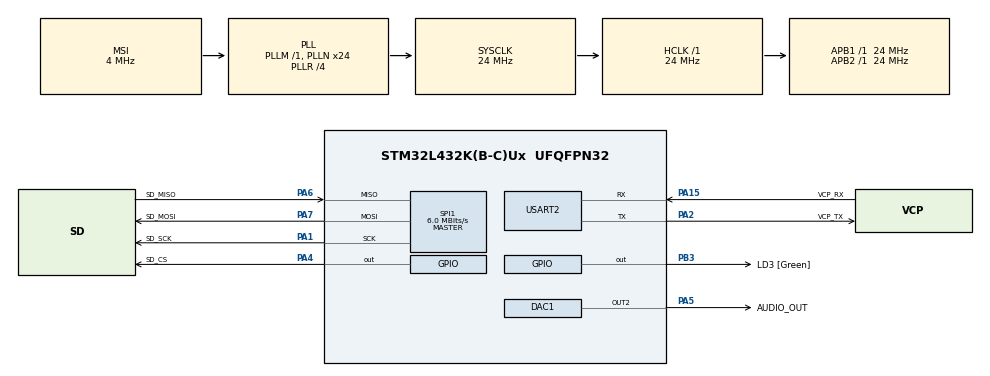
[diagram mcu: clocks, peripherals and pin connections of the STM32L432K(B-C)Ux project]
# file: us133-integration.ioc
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DAC1.DAC_Channel-DAC_OUT2=DAC_CHANNEL_2
DAC1.DAC_SampleAndHold-DAC_OUT2=DAC_SAMPLEANDHOLD_DISABLE
DAC1.DAC_Trigger-DAC_OUT2=DAC_TRIGGER_T6_TRGO
Dma.DAC_CH2.0.Direction=DMA_MEMORY_TO_PERIPH
Dma.DAC_CH2.0.Instance=DMA1_Channel4
Dma.DAC_CH2.0.MemDataAlignment=DMA_MDATAALIGN_HALFWORD
Dma.DAC_CH2.0.MemInc=DMA_MINC_ENABLE
Dma.DAC_CH2.0.Mode=DMA_CIRCULAR
Dma.DAC_CH2.0.PeriphDataAlignment=DMA_PDATAALIGN_HALFWORD
Dma.DAC_CH2.0.PeriphInc=DMA_PINC_DISABLE
Dma.DAC_CH2.0.Priority=DMA_PRIORITY_VERY_HIGH
Dma.Request0=DAC_CH2
FATFS._MAX_SS=4096
FREERTOS.BinarySemaphores01=SemPlayBlock01,Dynamic,NULL;SemPlayBlock02,Dynamic,NULL;SemSPI_SDcard,Dynamic,NULL
FREERTOS.Tasks01=sd_Card,24,128,StartSDCardTask,Default,NULL,Dynamic,NULL,NULL
FREERTOS.configUSE_IDLE_HOOK=1
FREERTOS.configUSE_NEWLIB_REENTRANT=1
FREERTOS.configUSE_TRACE_FACILITY=1
Mcu.Family=STM32L4
Mcu.Name=STM32L432K(B-C)Ux
Mcu.Package=UFQFPN32
NVIC.DMA1_Channel4_IRQn=true\:5\:0\:false\:false\:true\:true\:false\:true
NVIC.PriorityGroup=NVIC_PRIORITYGROUP_4
NVIC.TIM1_UP_TIM16_IRQn=true\:15\:0\:false\:false\:true\:false\:false\:true
NVIC.TimeBase=TIM1_UP_TIM16_IRQn
NVIC.TimeBaseIP=TIM16
PA0.GPIO_Label=MCO [High speed clock in]
PA0.Mode=HSE-External-Clock-Source-for-LittleOrca
PA0.Signal=RCC_CK_IN
PA1.GPIO_Label=SD_SCK
PA1.Mode=Full_Duplex_Master
PA1.Signal=SPI1_SCK
PA13\ (JTMS-SWDIO).GPIO_Label=SWDIO
PA13\ (JTMS-SWDIO).Mode=Serial_Wire
PA13\ (JTMS-SWDIO).Signal=SYS_JTMS-SWDIO
PA14\ (JTCK-SWCLK).GPIO_Label=SWCLK
PA14\ (JTCK-SWCLK).Mode=Serial_Wire
PA14\ (JTCK-SWCLK).Signal=SYS_JTCK-SWCLK
PA15\ (JTDI).GPIO_Label=VCP_RX
PA15\ (JTDI).Mode=Asynchronous
PA15\ (JTDI).Signal=USART2_RX
PA2.GPIO_Label=VCP_TX
PA2.Mode=Asynchronous
PA2.Signal=USART2_TX
PA4.GPIO_Label=SD_CS
PA4.Signal=GPIO_Output
PA5.GPIO_Label=AUDIO_OUT
PA5.Signal=COMP_DAC12_group
PA6.GPIO_Label=SD_MISO
PA6.Mode=Full_Duplex_Master
PA6.Signal=SPI1_MISO
PA7.GPIO_Label=SD_MOSI
PA7.Mode=Full_Duplex_Master
PA7.Signal=SPI1_MOSI
PB3\ (JTDO-TRACESWO).GPIO_Label=LD3 [Green]
PB3\ (JTDO-TRACESWO).Signal=GPIO_Output
PC14-OSC32_IN\ (PC14).Mode=LSE-External-Oscillator
PC14-OSC32_IN\ (PC14).Signal=RCC_OSC32_IN
PC15-OSC32_OUT\ (PC15).Mode=LSE-External-Oscillator
PC15-OSC32_OUT\ (PC15).Signal=RCC_OSC32_OUT
ProjectManager.HeapSize=0x200
ProjectManager.StackSize=0x400
ProjectManager.TargetToolchain=STM32CubeIDE
RCC.ADCFreq_Value=16000000
RCC.AHBFreq_Value=24000000
RCC.APB1Freq_Value=24000000
RCC.APB1TimFreq_Value=24000000
RCC.APB2Freq_Value=24000000
RCC.APB2TimFreq_Value=24000000
RCC.CortexFreq_Value=24000000
RCC.HCLKFreq_Value=24000000
RCC.HSE_VALUE=8000000
RCC.HSI16_VALUE=16000000
RCC.HSI48_VALUE=48000000
RCC.HSI_VALUE=16000000
RCC.MSI_VALUE=4000000
RCC.PLLMUL=RCC_PLLMUL_4
RCC.PLLN=24
RCC.PLLR=RCC_PLLR_DIV4
RCC.SYSCLKFreq_VALUE=24000000
RCC.SYSCLKSource=RCC_SYSCLKSOURCE_PLLCLK
RCC.USBFreq_Value=16000000
RCC.VCOOutputFreq_Value=96000000
SH.COMP_DAC12_group.0=DAC1_OUT2,DAC_OUT2
SPI1.BaudRatePrescaler=SPI_BAUDRATEPRESCALER_4
SPI1.CalculateBaudRate=6.0 MBits/s
SPI1.DataSize=SPI_DATASIZE_8BIT
SPI1.Direction=SPI_DIRECTION_2LINES
SPI1.Mode=SPI_MODE_MASTER
SPI1.VirtualType=VM_MASTER
TIM6.Period=500
USART2.VirtualMode-Asynchronous=VM_ASYNC
VP_FATFS_VS_Generic.Mode=User_defined
VP_FREERTOS_VS_CMSIS_V2.Mode=CMSIS_V2
VP_SYS_VS_tim16.Mode=TIM16
VP_TIM6_VS_ClockSourceINT.Mode=Enable_Timer
board=NUCLEO-L432KC

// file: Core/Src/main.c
/* USER CODE BEGIN Header */
/**
  ******************************************************************************
  * @file           : main.c
  * @brief          : Main program body
  ******************************************************************************
  * @attention
  *
  * <h2><center>&copy; Copyright (c) 2021 STMicroelectronics.
  * All rights reserved.</center></h2>
  *
  * This software component is licensed by ST under BSD 3-Clause license,
  * the "License"; You may not use this file except in compliance with the
  * License. You may obtain a copy of the License at:
  *                        opensource.org/licenses/BSD-3-Clause
  *
  ******************************************************************************
  */
/* USER CODE END Header */
#include "main.h"
#include "cmsis_os.h"
#include "fatfs.h"

DAC_HandleTypeDef hdac1;
DMA_HandleTypeDef hdma_dac_ch2;

SPI_HandleTypeDef hspi1;

TIM_HandleTypeDef htim6;

UART_HandleTypeDef huart2;

/* Definitions for sd_Card */
osThreadId_t sd_CardHandle;
const osThreadAttr_t sd_Card_attributes = {
  .name = "sd_Card",
  .stack_size = 128 * 4,
  .priority = (osPriority_t) osPriorityNormal,
};
/* Definitions for SemPlayBlock01 */
osSemaphoreId_t SemPlayBlock01Handle;
const osSemaphoreAttr_t SemPlayBlock01_attributes = {
  .name = "SemPlayBlock01"
};
/* Definitions for SemPlayBlock02 */
osSemaphoreId_t SemPlayBlock02Handle;
const osSemaphoreAttr_t SemPlayBlock02_attributes = {
  .name = "SemPlayBlock02"
};
/* Definitions for SemSPI_SDcard */
osSemaphoreId_t SemSPI_SDcardHandle;
const osSemaphoreAttr_t SemSPI_SDcard_attributes = {
  .name = "SemSPI_SDcard"
};
/* USER CODE BEGIN PV */
void audioPlayer_setup(void){

}
/* USER CODE END PV */

void SystemClock_Config(void);
static void MX_GPIO_Init(void);
static void MX_USART2_UART_Init(void);
static void MX_DMA_Init(void);
static void MX_DAC1_Init(void);
static void MX_TIM6_Init(void);
static void MX_SPI1_Init(void);
void StartSDCardTask(void *argument);

int main(void)
{

  /* MCU Configuration--------------------------------------------------------*/

  /* Reset of all peripherals, Initializes the Flash interface and the Systick. */
  HAL_Init();

  /* Configure the system clock */
  SystemClock_Config();

  /* Initialize all configured peripherals */
  MX_GPIO_Init();
  MX_USART2_UART_Init();
  MX_DMA_Init();
  MX_DAC1_Init();
  MX_TIM6_Init();
  MX_SPI1_Init();
  MX_FATFS_Init();

  /* Init scheduler */
  osKernelInitialize();

  /* Create the semaphores(s) */
  /* creation of SemPlayBlock01 */
  SemPlayBlock01Handle = osSemaphoreNew(1, 1, &SemPlayBlock01_attributes);

  /* creation of SemPlayBlock02 */
  SemPlayBlock02Handle = osSemaphoreNew(1, 1, &SemPlayBlock02_attributes);

  /* creation of SemSPI_SDcard */
  SemSPI_SDcardHandle = osSemaphoreNew(1, 1, &SemSPI_SDcard_attributes);

  /* Create the thread(s) */
  /* creation of sd_Card */
  sd_CardHandle = osThreadNew(StartSDCardTask, NULL, &sd_Card_attributes);

  /* Start scheduler */
  osKernelStart();

  /* We should never get here as control is now taken by the scheduler */
  /* Infinite loop */
  while (1)
  {

  }
}

void SystemClock_Config(void)
{
  RCC_OscInitTypeDef RCC_OscInitStruct = {0};
  RCC_ClkInitTypeDef RCC_ClkInitStruct = {0};

  /** Configure the main internal regulator output voltage
  */
  if (HAL_PWREx_ControlVoltageScaling(PWR_REGULATOR_VOLTAGE_SCALE1) != HAL_OK)
  {
    Error_Handler();
  }
  /** Configure LSE Drive Capability
  */
  HAL_PWR_EnableBkUpAccess();
  __HAL_RCC_LSEDRIVE_CONFIG(RCC_LSEDRIVE_LOW);
  /** Initializes the RCC Oscillators according to the specified parameters
  * in the RCC_OscInitTypeDef structure.
  */
  RCC_OscInitStruct.OscillatorType = RCC_OSCILLATORTYPE_LSE|RCC_OSCILLATORTYPE_MSI;
  RCC_OscInitStruct.LSEState = RCC_LSE_ON;
  RCC_OscInitStruct.MSIState = RCC_MSI_ON;
  RCC_OscInitStruct.MSICalibrationValue = 0;
  RCC_OscInitStruct.MSIClockRange = RCC_MSIRANGE_6;
  RCC_OscInitStruct.PLL.PLLState = RCC_PLL_ON;
  RCC_OscInitStruct.PLL.PLLSource = RCC_PLLSOURCE_MSI;
  RCC_OscInitStruct.PLL.PLLM = 1;
  RCC_OscInitStruct.PLL.PLLN = 24;
  RCC_OscInitStruct.PLL.PLLP = RCC_PLLP_DIV7;
  RCC_OscInitStruct.PLL.PLLQ = RCC_PLLQ_DIV2;
  RCC_OscInitStruct.PLL.PLLR = RCC_PLLR_DIV4;
  if (HAL_RCC_OscConfig(&RCC_OscInitStruct) != HAL_OK)
  {
    Error_Handler();
  }
  /** Initializes the CPU, AHB and APB buses clocks
  */
  RCC_ClkInitStruct.ClockType = RCC_CLOCKTYPE_HCLK|RCC_CLOCKTYPE_SYSCLK
                              |RCC_CLOCKTYPE_PCLK1|RCC_CLOCKTYPE_PCLK2;
  RCC_ClkInitStruct.SYSCLKSource = RCC_SYSCLKSOURCE_PLLCLK;
  RCC_ClkInitStruct.AHBCLKDivider = RCC_SYSCLK_DIV1;
  RCC_ClkInitStruct.APB1CLKDivider = RCC_HCLK_DIV1;
  RCC_ClkInitStruct.APB2CLKDivider = RCC_HCLK_DIV1;

  if (HAL_RCC_ClockConfig(&RCC_ClkInitStruct, FLASH_LATENCY_1) != HAL_OK)
  {
    Error_Handler();
  }
  /** Enable MSI Auto calibration
  */
  HAL_RCCEx_EnableMSIPLLMode();
}

static void MX_DAC1_Init(void)
{

  DAC_ChannelConfTypeDef sConfig = {0};

  /** DAC Initialization
  */
  hdac1.Instance = DAC1;
  if (HAL_DAC_Init(&hdac1) != HAL_OK)
  {
    Error_Handler();
  }
  /** DAC channel OUT2 config
  */
  sConfig.DAC_SampleAndHold = DAC_SAMPLEANDHOLD_DISABLE;
  sConfig.DAC_Trigger = DAC_TRIGGER_T6_TRGO;
  sConfig.DAC_OutputBuffer = DAC_OUTPUTBUFFER_ENABLE;
  sConfig.DAC_ConnectOnChipPeripheral = DAC_CHIPCONNECT_DISABLE;
  sConfig.DAC_UserTrimming = DAC_TRIMMING_FACTORY;
  if (HAL_DAC_ConfigChannel(&hdac1, &sConfig, DAC_CHANNEL_2) != HAL_OK)
  {
    Error_Handler();
  }

}

static void MX_SPI1_Init(void)
{

  /* SPI1 parameter configuration*/
  hspi1.Instance = SPI1;
  hspi1.Init.Mode = SPI_MODE_MASTER;
  hspi1.Init.Direction = SPI_DIRECTION_2LINES;
  hspi1.Init.DataSize = SPI_DATASIZE_8BIT;
  hspi1.Init.CLKPolarity = SPI_POLARITY_LOW;
  hspi1.Init.CLKPhase = SPI_PHASE_1EDGE;
  hspi1.Init.NSS = SPI_NSS_SOFT;
  hspi1.Init.BaudRatePrescaler = SPI_BAUDRATEPRESCALER_4;
  hspi1.Init.FirstBit = SPI_FIRSTBIT_MSB;
  hspi1.Init.TIMode = SPI_TIMODE_DISABLE;
  hspi1.Init.CRCCalculation = SPI_CRCCALCULATION_DISABLE;
  hspi1.Init.CRCPolynomial = 7;
  hspi1.Init.CRCLength = SPI_CRC_LENGTH_DATASIZE;
  hspi1.Init.NSSPMode = SPI_NSS_PULSE_ENABLE;
  if (HAL_SPI_Init(&hspi1) != HAL_OK)
  {
    Error_Handler();
  }

}

static void MX_TIM6_Init(void)
{

  TIM_MasterConfigTypeDef sMasterConfig = {0};

  htim6.Instance = TIM6;
  htim6.Init.Prescaler = 0;
  htim6.Init.CounterMode = TIM_COUNTERMODE_UP;
  htim6.Init.Period = 500;
  htim6.Init.AutoReloadPreload = TIM_AUTORELOAD_PRELOAD_DISABLE;
  if (HAL_TIM_Base_Init(&htim6) != HAL_OK)
  {
    Error_Handler();
  }
  sMasterConfig.MasterOutputTrigger = TIM_TRGO_RESET;
  sMasterConfig.MasterSlaveMode = TIM_MASTERSLAVEMODE_DISABLE;
  if (HAL_TIMEx_MasterConfigSynchronization(&htim6, &sMasterConfig) != HAL_OK)
  {
    Error_Handler();
  }

}

static void MX_USART2_UART_Init(void)
{

  huart2.Instance = USART2;
  huart2.Init.BaudRate = 115200;
  huart2.Init.WordLength = UART_WORDLENGTH_8B;
  huart2.Init.StopBits = UART_STOPBITS_1;
  huart2.Init.Parity = UART_PARITY_NONE;
  huart2.Init.Mode = UART_MODE_TX_RX;
  huart2.Init.HwFlowCtl = UART_HWCONTROL_NONE;
  huart2.Init.OverSampling = UART_OVERSAMPLING_16;
  huart2.Init.OneBitSampling = UART_ONE_BIT_SAMPLE_DISABLE;
  huart2.AdvancedInit.AdvFeatureInit = UART_ADVFEATURE_NO_INIT;
  if (HAL_UART_Init(&huart2) != HAL_OK)
  {
    Error_Handler();
  }

}

static void MX_DMA_Init(void)
{

  /* DMA controller clock enable */
  __HAL_RCC_DMA1_CLK_ENABLE();

  /* DMA interrupt init */
  /* DMA1_Channel4_IRQn interrupt configuration */
  HAL_NVIC_SetPriority(DMA1_Channel4_IRQn, 5, 0);
  HAL_NVIC_EnableIRQ(DMA1_Channel4_IRQn);

}

static void MX_GPIO_Init(void)
{
  GPIO_InitTypeDef GPIO_InitStruct = {0};

  /* GPIO Ports Clock Enable */
  __HAL_RCC_GPIOC_CLK_ENABLE();
  __HAL_RCC_GPIOA_CLK_ENABLE();
  __HAL_RCC_GPIOB_CLK_ENABLE();

  /*Configure GPIO pin Output Level */
  HAL_GPIO_WritePin(SD_CS_GPIO_Port, SD_CS_Pin, GPIO_PIN_RESET);

  /*Configure GPIO pin Output Level */
  HAL_GPIO_WritePin(LD3_GPIO_Port, LD3_Pin, GPIO_PIN_RESET);

  /*Configure GPIO pin : SD_CS_Pin */
  GPIO_InitStruct.Pin = SD_CS_Pin;
  GPIO_InitStruct.Mode = GPIO_MODE_OUTPUT_PP;
  GPIO_InitStruct.Pull = GPIO_NOPULL;
  GPIO_InitStruct.Speed = GPIO_SPEED_FREQ_LOW;
  HAL_GPIO_Init(SD_CS_GPIO_Port, &GPIO_InitStruct);

  /*Configure GPIO pin : LD3_Pin */
  GPIO_InitStruct.Pin = LD3_Pin;
  GPIO_InitStruct.Mode = GPIO_MODE_OUTPUT_PP;
  GPIO_InitStruct.Pull = GPIO_NOPULL;
  GPIO_InitStruct.Speed = GPIO_SPEED_FREQ_LOW;
  HAL_GPIO_Init(LD3_GPIO_Port, &GPIO_InitStruct);

}

void StartSDCardTask(void *argument)
{
  /* USER CODE BEGIN 5 */
  /* Infinite loop */
  for(;;)
  {
	//SM SDCard.
    osDelay(1);
  }
  /* USER CODE END 5 */
}

void HAL_TIM_PeriodElapsedCallback(TIM_HandleTypeDef *htim)
{
  if (htim->Instance == TIM16) {
    HAL_IncTick();
  }
}

void Error_Handler(void)
{
  __disable_irq();
  while (1)
  {
  }
}

/************************ (C) COPYRIGHT STMicroelectronics *****END OF FILE****/
